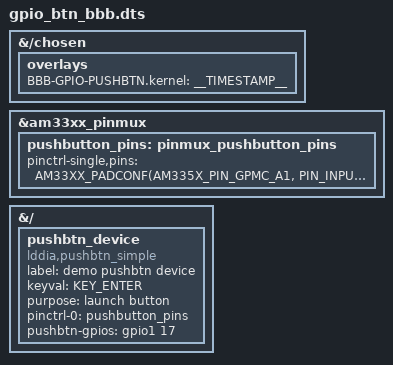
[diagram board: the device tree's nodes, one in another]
/*
 * DTSO - DT overlay source file
 *
 * DT overlay for the simple pushbutton platform input driver for the TI
 * BeagleBone Black (bbb) board.
 * This DTSO file MUST be placed within the target kernel source tree so that
 * it can be built via the 'make dtbs'; necessary as we include kernel headers
 * and employ macros like AM33XX_PADCONF(). 
 */
/dts-v1/;
/plugin/;

#include <dt-bindings/gpio/gpio.h>
#include <dt-bindings/pinctrl/am33xx.h>
#include "../../../../../../include/uapi/linux/input-event-codes.h"
#include <dt-bindings/interrupt-controller/irq.h>

/*
 * Helper to show loaded overlays under: /proc/device-tree/chosen/overlays/
 */
&{/chosen} {
	overlays {
		BBB-GPIO-PUSHBTN.kernel = __TIMESTAMP__;
	};
};

/*
 * VERY IMP
 * Typically, two sections of the DT (Overlay) need configuration:
 * - the PinMux, in order to make the required pin(s) functionality visible on
 *   the CPU/SoC pads, and
 * - the device itself, in order to launch and configure its device driver
 */

&am33xx_pinmux {
	pushbutton_pins: pinmux_pushbutton_pins {
		pinctrl-single,pins = <
		  AM33XX_PADCONF(AM335X_PIN_GPMC_A1, PIN_INPUT_PULLDOWN, MUX_MODE7)
		   /* (XYZ) GPMC_A1.GPIO1_17
		    * TI SoC pad / pin comment convention explained:
		    *  (XYZ)     : for k3 SoC's: actual package ball (when in
		    *              a BGA SoC package. Tip: use TI SysConfig
		    *              GUI to see it!)
		    *  GPMC_A1   : primary - Mux Mode0 - name on pad
		    *            (identifies the pad, never changes)
		    *  .GPIO1_17 : function actually selected
		    *  (GPMC = General Purpose Memory Controller)
		    *  In addition, this pin on the board (BBB) is:
		    *   P9_23, pushbutton connected to 3V3
		    */
	                    >;
	/*
	 * Ref: BeagleBone Black System Reference Manual (SRM), 2025 (PDF):
	 * https://github.com/beagleboard/beaglebone-black/blob/master/BBB_SRM.pdf
	 *  where: Connectors / Expansion Connectors / Connector P9   (pg 67,68)
	 *
	 * GPIO_49 is phy pin P9_23, CPU pin V14, pin name GPIO_17, mode 0 gpmc_a1;
	 * It's at pinmux reg offset AM335X_PIN_GPMC_A1 (=0x844), and 'mode 7'
	 * maps to 'gpio1[17]'! Always use mode 7 for GPIO.
	 */
	};
};

&{/} {
        /* Create a (pseudo) on-chip peripheral (ocp) named 'pushbtn_device' */
        pushbtn_device {
		compatible = "lddia,pushbtn_simple";
		label = "demo pushbtn device";
		keyval = <KEY_ENTER>;
		//keyval = <KEY_ASSISTANT>;
				/* the actual input event key or button
				 * emananted by our pushbutton */
		purpose = "launch button";
		pinctrl-names = "default";
		pinctrl-0 = <&pushbutton_pins>; /* link to the PinMux */

		pushbtn-gpios = <&gpio1 17 GPIO_ACTIVE_HIGH>; // for P9_23
		/*
		 * Explanation for the above line:
		 * format for gpio: 
		 *  <name>-gpios = <&GPIO-phandle GPIO-offset-in-bank  consumer-flags>;
		 *        1              2               3                    4
		 * So:
		 *  1. <name>-gpios = pushbtn-gpios ; the name prefix 'pushbtn' reflects the
		 *    purpose of this GPIO for the device
		 *  2. &gpio1 : the GPIO handle, refers to GPIO bank #1
		 *  3. 17 : the GPIO bank offset:
		 *     Method 1:
		 *     Lookup the BBB SRM : Table 13. Expansion Header P9 Pinout
	         * PIN PROC NAME    MODE0   MODE1 MODE2 MODE3       MODE4     MODE5    MODE6         MODE7
	         * 23 V14 GPIO1_17 gpmc_a1 gmii2_rxdv  rgmii2_rxdv mmc2_dat0 gpmc_a17 ehrpwm0_synco gpio1[17]
	         * The NAME col shows GPIO_17 ; so the GPIO bank offset is 17.
	         * (FYI: The GPIO bank is 1 (as it shows as NAME is GPIO1_17).
		 *  PROC is the pin number on the processor.)
		 *       Method 2:
		 * grep '44e10844' /sys/kernel/debug/pinctrl/44e10800.pinmux-pinctrl-single/pins
		 * pin 17 (PIN17) 17:gpio-0-31 44e10844 00000027 pinctrl-single
		 *                ^^
		 *	          GPIO offset!
		 *  4. GPIO_ACTIVE_HIGH : the GPIO flag; sets the pin specified to active high state
		 *  Ref: arch/arm/boot/dts/ti/omap/am335x-boneblack.dts
		 *   https://elixir.bootlin.com/linux/v6.18.33/source/Documentation/devicetree/bindings/gpio/gpio.txt
		 */

		/* FYI: we could use these properties to describe the interrupt model:
		 *	interrupt-parent = <&gpio1>;
		 *	interrupts = <17 IRQ_TYPE_EDGE_BOTH>;
		 * However, this  sacrifices the ability to use the devm_gpiod_get() etc in
		 * the driver! So, we don't do this; instead, in the driver, we employ the
		 * devm_gpiod_get() and gpiod_to_irq() routines to fetch the allocated IRQ line.
		 */
		status = "okay";
	};
};
